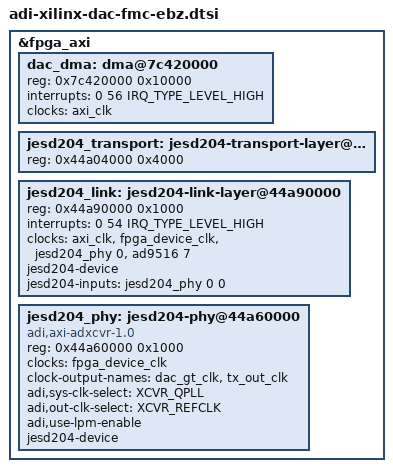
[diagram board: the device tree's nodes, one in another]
#include <dt-bindings/jesd204/adxcvr.h>

&fpga_axi {
	dac_dma: dma@7c420000 {
		reg = <0x7c420000 0x10000>;

		interrupts = <0 56 IRQ_TYPE_LEVEL_HIGH>;
		clocks = <&axi_clk>;
	};

	jesd204_transport: jesd204-transport-layer@44a04000 {
		reg = <0x44a04000 0x4000>;
	};

	jesd204_link: jesd204-link-layer@44a90000 {
		reg = <0x44a90000 0x1000>;

		interrupts = <0 54 IRQ_TYPE_LEVEL_HIGH>;

		clocks = <&axi_clk>, <&fpga_device_clk>, <&jesd204_phy 0>, <&ad9516 7>;
		clock-names = "s_axi_aclk", "device_clk", "lane_clk", "sysref_clk";

		/* jesd204-fsm support */
		jesd204-device;
		#jesd204-cells = <2>;
		jesd204-inputs = <&jesd204_phy 0 0>;
	};

	jesd204_phy: jesd204-phy@44a60000 {
		compatible = "adi,axi-adxcvr-1.0";
		reg = <0x44a60000 0x1000>;

		clocks = <&fpga_device_clk>;
		clock-names = "conv";

		#clock-cells = <1>;
		clock-output-names = "dac_gt_clk", "tx_out_clk";

		adi,sys-clk-select = <XCVR_QPLL>;
		adi,out-clk-select = <XCVR_REFCLK>;
		adi,use-lpm-enable;

		/* jesd204-fsm support */
		jesd204-device;
		#jesd204-cells = <2>;
	};
};

#include "adi-common-dac-fmc-ebz.dtsi"
